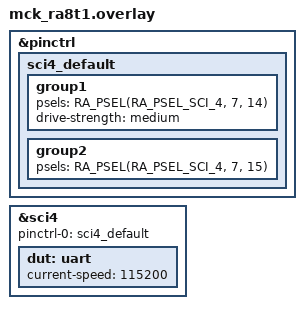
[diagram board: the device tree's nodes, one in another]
/*
 * Copyright (c) 2024 Renesas Electronics Corporation
 * SPDX-License-Identifier: Apache-2.0
 */

&pinctrl {
	sci4_default: sci4_default {
		group1 {
			/* tx */
			psels = <RA_PSEL(RA_PSEL_SCI_4, 7, 14)>;
			drive-strength = "medium";
		};
		group2 {
			/* rx */
			psels = <RA_PSEL(RA_PSEL_SCI_4, 7, 15)>;
		};
	};
};

&sci4 {
	pinctrl-0 = <&sci4_default>;
	pinctrl-names = "default";
	status = "okay";
	dut: uart {
		current-speed = <115200>;
		status = "okay";
	};
};
